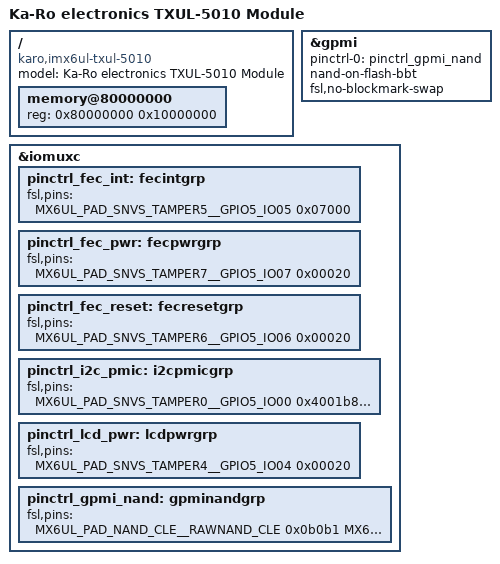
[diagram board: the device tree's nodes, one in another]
// SPDX-License-Identifier: GPL-2.0+
/*
 * Copyright (C) 2026 Ka-Ro Electronics GmbH
 * Ka-Ro TXUL-5010 module (i.MX6UL)
 */

/dts-v1/;

#include "imx6ul.dtsi"
#include <dt-bindings/gpio/gpio.h>
#include "imx6ul-txul.dtsi"

/ {
	model = "Ka-Ro electronics TXUL-5010 Module";
	compatible = "karo,imx6ul-txul-5010", "fsl,imx6ul";

	memory@80000000 {
		device_type = "memory";
		reg = <0x80000000 0x10000000>;	/* 256 MiB DDR3 */
	};
};

&gpmi {
	pinctrl-names = "default";
	pinctrl-0 = <&pinctrl_gpmi_nand>;
	nand-on-flash-bbt;
	fsl,no-blockmark-swap;
	status = "okay";
};

&iomuxc {
	pinctrl_fec_int: fecintgrp {
		fsl,pins = <
			MX6UL_PAD_SNVS_TAMPER5__GPIO5_IO05	0x07000
		>;
	};

	pinctrl_fec_pwr: fecpwrgrp {
		fsl,pins = <
			MX6UL_PAD_SNVS_TAMPER7__GPIO5_IO07	0x00020
		>;
	};

	pinctrl_fec_reset: fecresetgrp {
		fsl,pins = <
			MX6UL_PAD_SNVS_TAMPER6__GPIO5_IO06	0x00020
		>;
	};

	pinctrl_i2c_pmic: i2cpmicgrp {
		fsl,pins = <
			MX6UL_PAD_SNVS_TAMPER0__GPIO5_IO00	0x4001b8b1
			MX6UL_PAD_SNVS_TAMPER1__GPIO5_IO01	0x4001b8b1
		>;
	};

	pinctrl_lcd_pwr: lcdpwrgrp {
		fsl,pins = <
			MX6UL_PAD_SNVS_TAMPER4__GPIO5_IO04	0x00020
		>;
	};

	pinctrl_gpmi_nand: gpminandgrp {
		fsl,pins = <
			MX6UL_PAD_NAND_CLE__RAWNAND_CLE		0x0b0b1
			MX6UL_PAD_NAND_ALE__RAWNAND_ALE		0x0b0b1
			MX6UL_PAD_NAND_WP_B__RAWNAND_WP_B	0x0b0b1
			MX6UL_PAD_NAND_READY_B__RAWNAND_READY_B	0x0b000
			MX6UL_PAD_NAND_CE0_B__RAWNAND_CE0_B	0x0b0b1
			MX6UL_PAD_NAND_RE_B__RAWNAND_RE_B	0x0b0b1
			MX6UL_PAD_NAND_WE_B__RAWNAND_WE_B	0x0b0b1
			MX6UL_PAD_NAND_DATA00__RAWNAND_DATA00	0x0b0b1
			MX6UL_PAD_NAND_DATA01__RAWNAND_DATA01	0x0b0b1
			MX6UL_PAD_NAND_DATA02__RAWNAND_DATA02	0x0b0b1
			MX6UL_PAD_NAND_DATA03__RAWNAND_DATA03	0x0b0b1
			MX6UL_PAD_NAND_DATA04__RAWNAND_DATA04	0x0b0b1
			MX6UL_PAD_NAND_DATA05__RAWNAND_DATA05	0x0b0b1
			MX6UL_PAD_NAND_DATA06__RAWNAND_DATA06	0x0b0b1
			MX6UL_PAD_NAND_DATA07__RAWNAND_DATA07	0x0b0b1
		>;
	};
};
